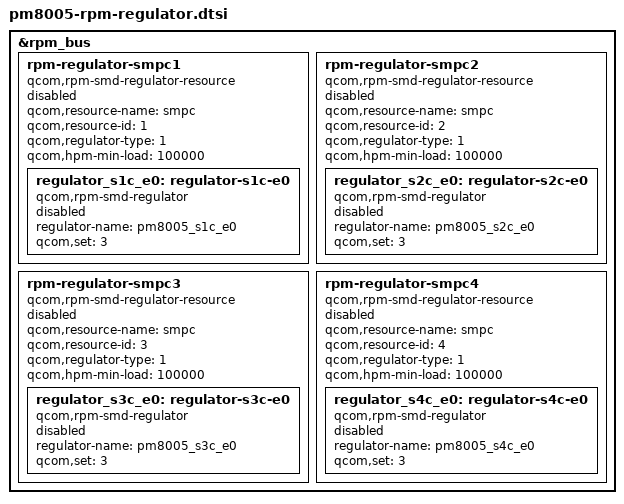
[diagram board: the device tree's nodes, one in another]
// SPDX-License-Identifier: BSD-3-Clause
/*
 * Copyright (c) Qualcomm Technologies, Inc. and/or its subsidiaries.
 */

&rpm_bus {
	/* SMPS Regulators - PM8005 */
	rpm-regulator-smpc1 {
		compatible = "qcom,rpm-smd-regulator-resource";
		qcom,resource-name = "smpc";
		qcom,resource-id = <1>;
		qcom,regulator-type = <1>;
		qcom,hpm-min-load = <100000>;
		status = "disabled";

		regulator_s1c_e0: regulator-s1c-e0 {
			compatible = "qcom,rpm-smd-regulator";
			regulator-name = "pm8005_s1c_e0";
			qcom,set = <3>;
			status = "disabled";
		};
	};

	rpm-regulator-smpc2 {
		compatible = "qcom,rpm-smd-regulator-resource";
		qcom,resource-name = "smpc";
		qcom,resource-id = <2>;
		qcom,regulator-type = <1>;
		qcom,hpm-min-load = <100000>;
		status = "disabled";

		regulator_s2c_e0: regulator-s2c-e0 {
			compatible = "qcom,rpm-smd-regulator";
			regulator-name = "pm8005_s2c_e0";
			qcom,set = <3>;
			status = "disabled";
		};
	};

	rpm-regulator-smpc3 {
		compatible = "qcom,rpm-smd-regulator-resource";
		qcom,resource-name = "smpc";
		qcom,resource-id = <3>;
		qcom,regulator-type = <1>;
		qcom,hpm-min-load = <100000>;
		status = "disabled";

		regulator_s3c_e0: regulator-s3c-e0 {
			compatible = "qcom,rpm-smd-regulator";
			regulator-name = "pm8005_s3c_e0";
			qcom,set = <3>;
			status = "disabled";
		};
	};

	rpm-regulator-smpc4 {
		compatible = "qcom,rpm-smd-regulator-resource";
		qcom,resource-name = "smpc";
		qcom,resource-id = <4>;
		qcom,regulator-type = <1>;
		qcom,hpm-min-load = <100000>;
		status = "disabled";

		regulator_s4c_e0: regulator-s4c-e0 {
			compatible = "qcom,rpm-smd-regulator";
			regulator-name = "pm8005_s4c_e0";
			qcom,set = <3>;
			status = "disabled";
		};
	};
};
